# MIMXRT1021 register map
Vendor: nxp.com; File version: 1.0
CPU: CM7 r0p1, little endian, MPU, FPU, VTOR, 4 interrupt priority bits
Registers are 32-bit, read-write, reset 0x0 unless marked. A register's access mark holds for its fields unless they carry their own. Offsets are from the block's base; [hi:lo] are bit positions; {n}, {i} and the like mark numbered series; 'fields as' and 'values as' point back to an identical list.

## PGC
Base 0x400F4000; register names take the prefix PGC_; alternate view of GPC
0x220 MEGA_CTRL — PGC Mega Control Register
  [0] PCR — Power Control PCR must not change from power-down request (pdn_req) assertion until the target subsystem is completely powered up
    0=Do not switch off power even if pdn_req is asserted; 1=Switch off power when pdn_req is asserted
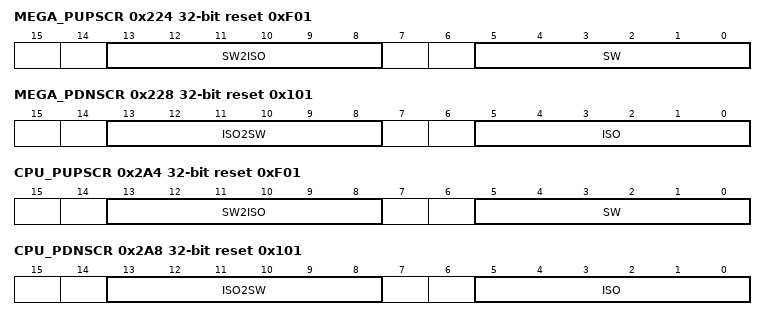
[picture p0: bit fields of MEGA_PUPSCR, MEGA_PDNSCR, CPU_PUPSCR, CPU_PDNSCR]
0x224 MEGA_PUPSCR reset 0xF01 — PGC Mega Power Up Sequence Control Register
  [13:8] SW2ISO — After asserting power toggle on/off signal (switch_b) to switch on power, the PGC waits a number of IPG clocks equal to the value of SW2ISO before negating isolation
  [5:0] SW — After a power-up request (pup_req assertion), the PGC waits a number of IPG clocks equal to the value of SW before asserting power toggle on/off signal (switch_b) to switch on power
0x228 MEGA_PDNSCR reset 0x101 — PGC Mega Pull Down Sequence Control Register
  [13:8] ISO2SW — After asserting isolation, the PGC waits a number of IPG clocks equal to the value of ISO2SW before negating power toggle on/off signal (switch_b) to switch off power
  [5:0] ISO — After a power-down request (pdn_req assertion), the PGC waits a number of IPG clocks equal to the value of ISO before asserting isolation
0x22C MEGA_SR — PGC Mega Power Gating Controller Status Register
  [0] PSR — Power status
    0=The target subsystem was not powered down for the previous power-down request; 1=The target subsystem was powered down for the previous power-down request
0x2A0 CPU_CTRL — PGC CPU Control Register
  fields as MEGA_CTRL
0x2A4 CPU_PUPSCR reset 0xF01 — PGC CPU Power Up Sequence Control Register
  fields as MEGA_PUPSCR
0x2A8 CPU_PDNSCR reset 0x101 — PGC CPU Pull Down Sequence Control Register
  fields as MEGA_PDNSCR
0x2AC CPU_SR — PGC CPU Power Gating Controller Status Register
  fields as MEGA_SR

## GPIO1 — GPIO
Base 0x401B8000
Same registers: GPIO5 0x400C0000, GPIO2 0x401BC000, GPIO3 0x401C0000
0x00 DR — GPIO data register
  [31:0] DR — DR data bits
0x04 GDIR — GPIO direction register
  [31:0] GDIR — GPIO direction bits
0x08 PSR ro — GPIO pad status register
  [31:0] PSR — GPIO pad status bits
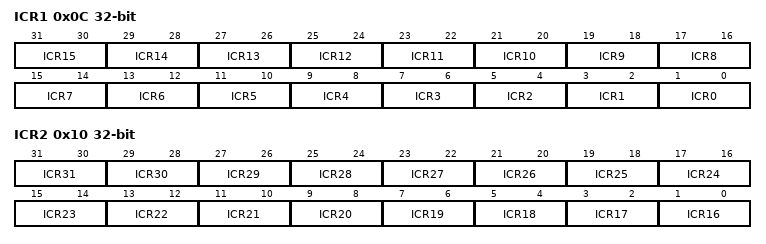
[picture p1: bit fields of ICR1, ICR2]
0x0C ICR1 — GPIO interrupt configuration register1
  [2n+1:2n] ICR{n} (n=0..15) — Interrupt configuration field for GPIO interrupt {n}
    0=LOW_LEVEL (Interrupt {n} is low-level sensitive.); 1=HIGH_LEVEL (Interrupt {n} is high-level sensitive.); 2=RISING_EDGE (Interrupt {n} is rising-edge sensitive.); 3=FALLING_EDGE (Interrupt {n} is falling-edge sensitive.)
0x10 ICR2 — GPIO interrupt configuration register2
  [2n-31:2n-32] ICR{n} (n=16..31) — Interrupt configuration field for GPIO interrupt {n}
    values as ICR1.ICR0
0x14 IMR — GPIO interrupt mask register
  [31:0] IMR — Interrupt Mask bits
0x18 ISR write-1-clears — GPIO interrupt status register
  [31:0] ISR write-1-clears — Interrupt status bits
0x1C EDGE_SEL — GPIO edge select register
  [31:0] GPIO_EDGE_SEL — Edge select
0x84 DR_SET wo — GPIO data register SET
  [31:0] DR_SET — Set
0x88 DR_CLEAR wo — GPIO data register CLEAR
  [31:0] DR_CLEAR — Clear
0x8C DR_TOGGLE wo — GPIO data register TOGGLE
  [31:0] DR_TOGGLE — Toggle

## KPP — KPP Registers
Base 0x401FC000; register names take the prefix KPP_
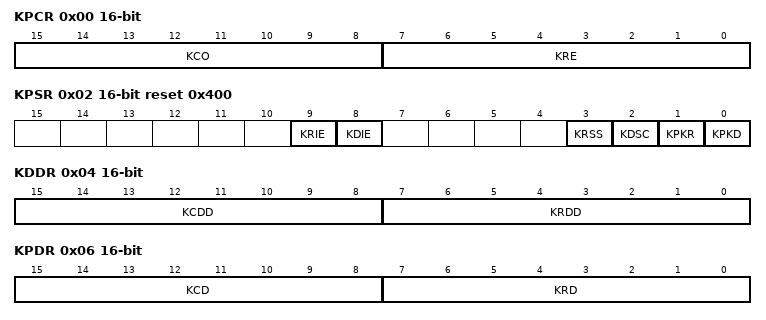
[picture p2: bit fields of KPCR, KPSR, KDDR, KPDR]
0x00 KPCR 16-bit — Keypad Control Register
  [15:8] KCO — Keypad Column Strobe Open-Drain Enable
    0=TOTEM_POLE (Column strobe output is totem pole drive.); 1=OPEN_DRAIN (Column strobe output is open drain.)
  [7:0] KRE — Keypad Row Enable
    0=Row is not included in the keypad key press detect; 1=Row is included in the keypad key press detect
0x02 KPSR 16-bit reset 0x400 — Keypad Status Register
  [9] KRIE — Keypad Release Interrupt Enable
    0=No interrupt request is generated when KPKR is set; 1=An interrupt request is generated when KPKR is set
  [8] KDIE — Keypad Key Depress Interrupt Enable
    0=No interrupt request is generated when KPKD is set; 1=An interrupt request is generated when KPKD is set
  [3] KRSS — Key Release Synchronizer Set
    0=No effect; 1=Set bits which sets keypad release synchronizer chain
  [2] KDSC — Key Depress Synchronizer Clear
    0=No effect; 1=Set bits that clear the keypad depress synchronizer chain
  [1] KPKR write-1-clears — Keypad Key Release
    0=No key release detected; 1=All keys have been released
  [0] KPKD write-1-clears — Keypad Key Depress
    0=No key presses detected; 1=A key has been depressed
0x04 KDDR 16-bit — Keypad Data Direction Register
  [15:8] KCDD — Keypad Column Data Direction Register
    0=INPUT (COLn pin is configured as an input.); 1=OUTPUT (COLn pin is configured as an output.)
  [7:0] KRDD — Keypad Row Data Direction
    0=INPUT (ROWn pin configured as an input.); 1=OUTPUT (ROWn pin configured as an output.)
0x06 KPDR 16-bit — Keypad Data Register
  [15:8] KCD — Keypad Column Data
  [7:0] KRD — Keypad Row Data
